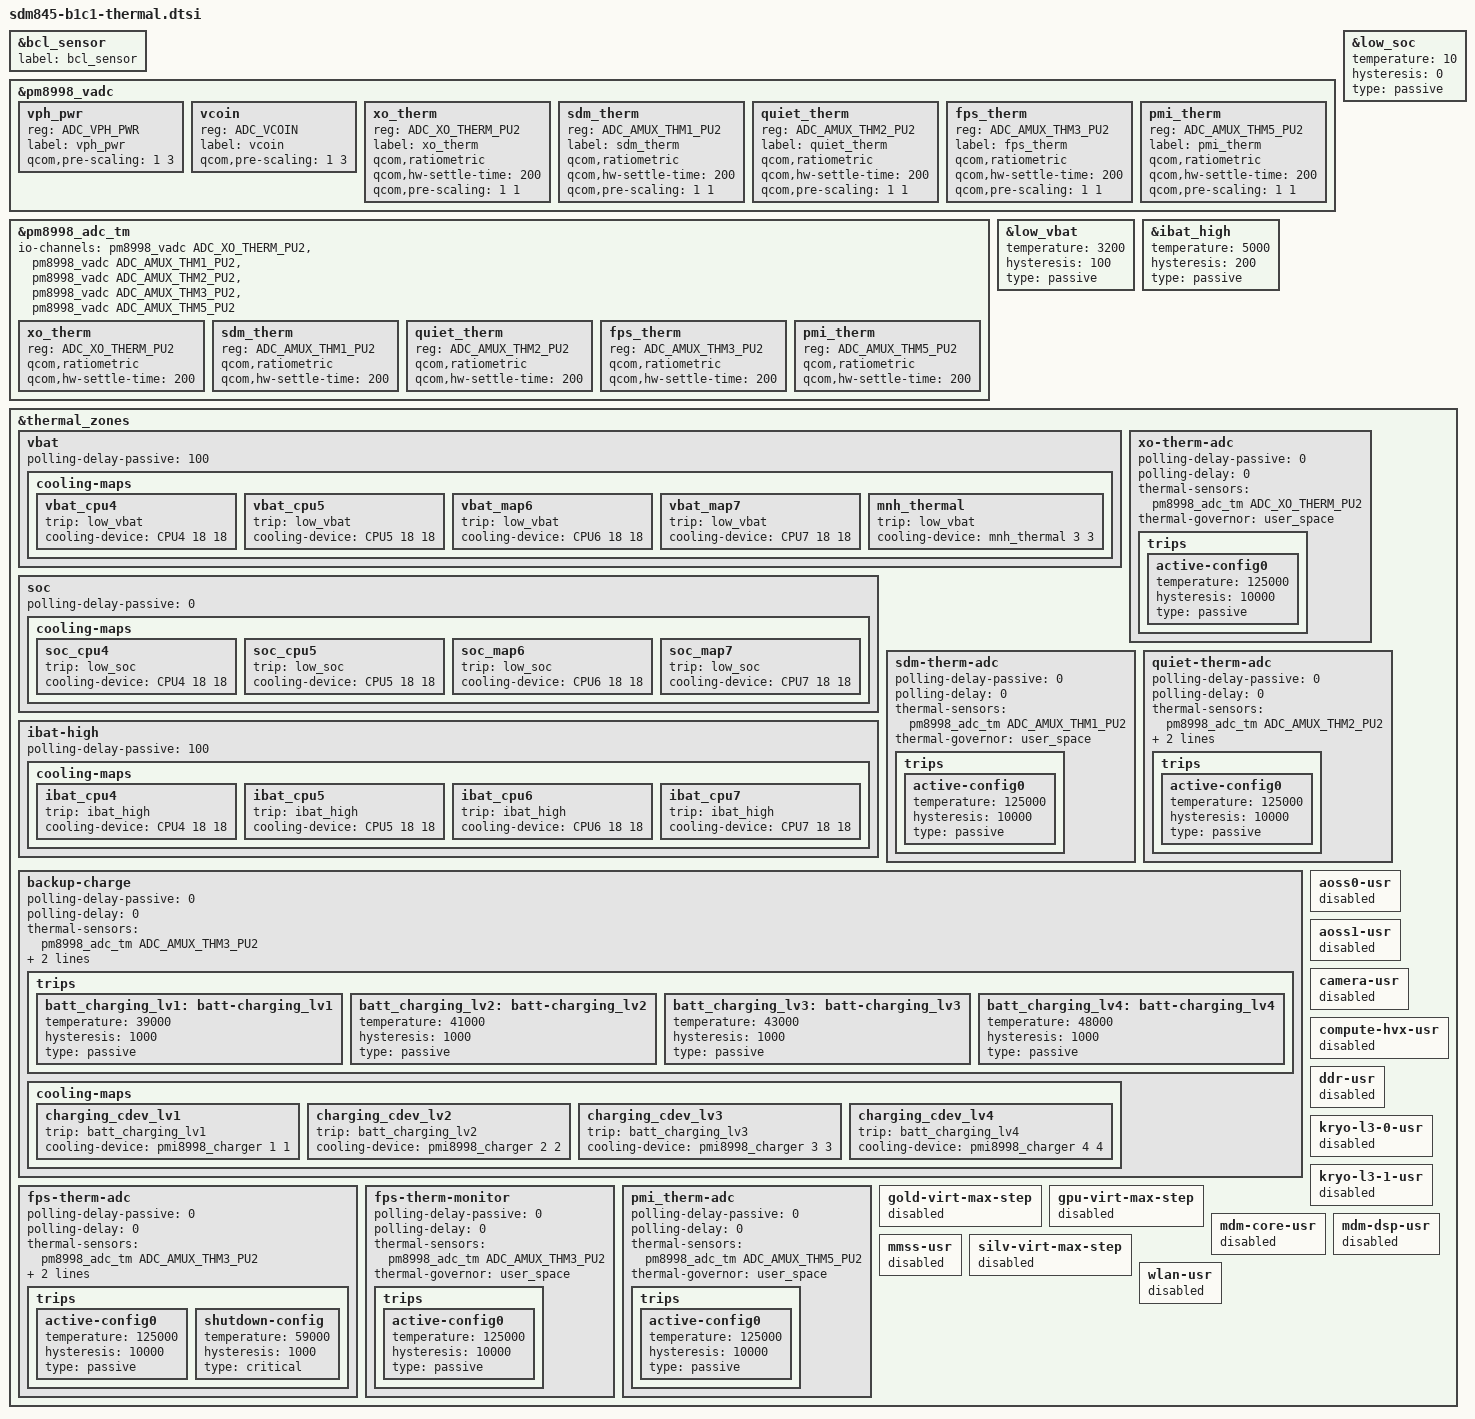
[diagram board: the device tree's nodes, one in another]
#include <dt-bindings/iio/qcom,spmi-vadc.h>


&bcl_sensor {
	label = "bcl_sensor";
};

/*
 * msm-4.14 ADC bindings (qcom,spmi-adc-rev2 / qcom,adc-tm-rev2). The
 * msm-4.9 qpnp-vadc-hc nodes had no driver here, so every board
 * thermistor zone read back -EINVAL.
 */
&pm8998_vadc {
	vph_pwr {
		reg = <ADC_VPH_PWR>;
		label = "vph_pwr";
		qcom,pre-scaling = <1 3>;
	};

	vcoin {
		reg = <ADC_VCOIN>;
		label = "vcoin";
		qcom,pre-scaling = <1 3>;
	};

	xo_therm {
		reg = <ADC_XO_THERM_PU2>;
		label = "xo_therm";
		qcom,ratiometric;
		qcom,hw-settle-time = <200>;
		qcom,pre-scaling = <1 1>;
	};

	sdm_therm {
		reg = <ADC_AMUX_THM1_PU2>;
		label = "sdm_therm";
		qcom,ratiometric;
		qcom,hw-settle-time = <200>;
		qcom,pre-scaling = <1 1>;
	};

	quiet_therm {
		reg = <ADC_AMUX_THM2_PU2>;
		label = "quiet_therm";
		qcom,ratiometric;
		qcom,hw-settle-time = <200>;
		qcom,pre-scaling = <1 1>;
	};

	fps_therm {
		reg = <ADC_AMUX_THM3_PU2>;
		label = "fps_therm";
		qcom,ratiometric;
		qcom,hw-settle-time = <200>;
		qcom,pre-scaling = <1 1>;
	};

	pmi_therm {
		reg = <ADC_AMUX_THM5_PU2>;
		label = "pmi_therm";
		qcom,ratiometric;
		qcom,hw-settle-time = <200>;
		qcom,pre-scaling = <1 1>;
	};
};

&pm8998_adc_tm {
	io-channels = <&pm8998_vadc ADC_XO_THERM_PU2>,
		      <&pm8998_vadc ADC_AMUX_THM1_PU2>,
		      <&pm8998_vadc ADC_AMUX_THM2_PU2>,
		      <&pm8998_vadc ADC_AMUX_THM3_PU2>,
		      <&pm8998_vadc ADC_AMUX_THM5_PU2>;

	xo_therm {
		reg = <ADC_XO_THERM_PU2>;
		qcom,ratiometric;
		qcom,hw-settle-time = <200>;
	};

	sdm_therm {
		reg = <ADC_AMUX_THM1_PU2>;
		qcom,ratiometric;
		qcom,hw-settle-time = <200>;
	};

	quiet_therm {
		reg = <ADC_AMUX_THM2_PU2>;
		qcom,ratiometric;
		qcom,hw-settle-time = <200>;
	};

	fps_therm {
		reg = <ADC_AMUX_THM3_PU2>;
		qcom,ratiometric;
		qcom,hw-settle-time = <200>;
	};

	pmi_therm {
		reg = <ADC_AMUX_THM5_PU2>;
		qcom,ratiometric;
		qcom,hw-settle-time = <200>;
	};
};

&low_vbat {
	temperature = <3200>;
	hysteresis = <100>;
	type = "passive";
};

&low_soc {
	temperature = <10>;
	hysteresis = <0>;
	type = "passive";
};

&ibat_high {
	temperature = <5000>;
	hysteresis = <200>;
	type = "passive";
};

&thermal_zones {
	vbat {
		polling-delay-passive = <100>;
		cooling-maps {
			vbat_cpu4 {
				trip = <&low_vbat>;
				cooling-device =
					<&CPU4 18 18>;
			};
			vbat_cpu5 {
				trip = <&low_vbat>;
				cooling-device =
					<&CPU5 18 18>;
			};
			vbat_map6 {
				trip = <&low_vbat>;
				cooling-device =
					<&CPU6 18 18>;
			};
			vbat_map7 {
				trip = <&low_vbat>;
				cooling-device =
					<&CPU7 18 18>;
			};
			mnh_thermal {
				trip = <&low_vbat>;
				cooling-device =
					<&mnh_thermal 3 3>;
			};
		};
	};
	soc {
		polling-delay-passive = <0>;
		cooling-maps {
			soc_cpu4 {
				trip = <&low_soc>;
				cooling-device =
					<&CPU4 18 18>;
			};
			soc_cpu5 {
				trip = <&low_soc>;
				cooling-device =
					<&CPU5 18 18>;
			};
			soc_map6 {
				trip = <&low_soc>;
				cooling-device =
					<&CPU6 18 18>;
			};
			soc_map7 {
				trip = <&low_soc>;
				cooling-device =
					<&CPU7 18 18>;
			};
		};
	};
	ibat-high {
		polling-delay-passive = <100>;
		cooling-maps {
			ibat_cpu4 {
				trip = <&ibat_high>;
				cooling-device =
					<&CPU4 18 18>;
			};
			ibat_cpu5 {
				trip = <&ibat_high>;
				cooling-device =
					<&CPU5 18 18>;
			};
			ibat_cpu6 {
				trip = <&ibat_high>;
				cooling-device =
					<&CPU6 18 18>;
			};
			ibat_cpu7 {
				trip = <&ibat_high>;
				cooling-device =
					<&CPU7 18 18>;
			};
		};
	};

	xo-therm-adc {
		polling-delay-passive = <0>;
		polling-delay = <0>;
		thermal-sensors = <&pm8998_adc_tm ADC_XO_THERM_PU2>;
		thermal-governor = "user_space";

		trips {
			active-config0 {
				temperature = <125000>;
				hysteresis = <10000>;
				type = "passive";
			};
		};
	};

	sdm-therm-adc {
		polling-delay-passive = <0>;
		polling-delay = <0>;
		thermal-sensors = <&pm8998_adc_tm ADC_AMUX_THM1_PU2>;
		thermal-governor = "user_space";

		trips {
			active-config0 {
				temperature = <125000>;
				hysteresis = <10000>;
				type = "passive";
			};
		};
	};

	quiet-therm-adc {
		polling-delay-passive = <0>;
		polling-delay = <0>;
		thermal-sensors = <&pm8998_adc_tm ADC_AMUX_THM2_PU2>;
		thermal-governor = "user_space";
		disable-thermal-zone;

		trips {
			active-config0 {
				temperature = <125000>;
				hysteresis = <10000>;
				type = "passive";
			};
		};
	};

	backup-charge {
		polling-delay-passive = <0>;
		polling-delay = <0>;
		thermal-sensors = <&pm8998_adc_tm ADC_AMUX_THM3_PU2>;
		thermal-governor = "step_wise";
		disable-thermal-zone;

		trips {
			batt_charging_lv1: batt-charging_lv1 {
				temperature = <39000>;
				hysteresis = <1000>;
				type = "passive";
			};
			batt_charging_lv2: batt-charging_lv2 {
				temperature = <41000>;
				hysteresis = <1000>;
				type = "passive";
			};
			batt_charging_lv3: batt-charging_lv3 {
				temperature = <43000>;
				hysteresis = <1000>;
				type = "passive";
			};
			batt_charging_lv4: batt-charging_lv4 {
				temperature = <48000>;
				hysteresis = <1000>;
				type = "passive";
			};
		};
		cooling-maps {
			charging_cdev_lv1 {
				trip = <&batt_charging_lv1>;
				cooling-device = <&pmi8998_charger 1 1>;
			};
			charging_cdev_lv2 {
				trip = <&batt_charging_lv2>;
				cooling-device = <&pmi8998_charger 2 2>;
			};
			charging_cdev_lv3 {
				trip = <&batt_charging_lv3>;
				cooling-device = <&pmi8998_charger 3 3>;
			};
			charging_cdev_lv4 {
				trip = <&batt_charging_lv4>;
				cooling-device = <&pmi8998_charger 4 4>;
			};
		};
	};

	fps-therm-adc {
		polling-delay-passive = <0>;
		polling-delay = <0>;
		thermal-sensors = <&pm8998_adc_tm ADC_AMUX_THM3_PU2>;
		thermal-governor = "user_space";
		disable-thermal-zone;

		trips {
			active-config0 {
				temperature = <125000>;
				hysteresis = <10000>;
				type = "passive";
			};
			shutdown-config {
				temperature = <59000>;
				hysteresis = <1000>;
				type = "critical";
			};
		};
	};

	fps-therm-monitor {
		polling-delay-passive = <0>;
		polling-delay = <0>;
		thermal-sensors = <&pm8998_adc_tm ADC_AMUX_THM3_PU2>;
		thermal-governor = "user_space";

		trips {
			active-config0 {
				temperature = <125000>;
				hysteresis = <10000>;
				type = "passive";
			};
		};
	};

	pmi_therm-adc {
		polling-delay-passive = <0>;
		polling-delay = <0>;
		thermal-sensors = <&pm8998_adc_tm ADC_AMUX_THM5_PU2>;
		thermal-governor = "user_space";

		trips {
			active-config0 {
				temperature = <125000>;
				hysteresis = <10000>;
				type = "passive";
			};
		};
	};

	aoss0-usr {
		status = "disabled";
	};

	aoss1-usr {
		status = "disabled";
	};

	camera-usr {
		status = "disabled";
	};

	compute-hvx-usr {
		status = "disabled";
	};

	ddr-usr {
		status = "disabled";
	};

	gold-virt-max-step {
		status = "disabled";
	};

	gpu-virt-max-step {
		status = "disabled";
	};

	kryo-l3-0-usr {
		status = "disabled";
	};

	kryo-l3-1-usr {
		status = "disabled";
	};

	mdm-core-usr {
		status = "disabled";
	};

	mdm-dsp-usr {
		status = "disabled";
	};

	mmss-usr {
		status = "disabled";
	};

	silv-virt-max-step {
		status = "disabled";
	};

	wlan-usr {
		status = "disabled";
	};
};
